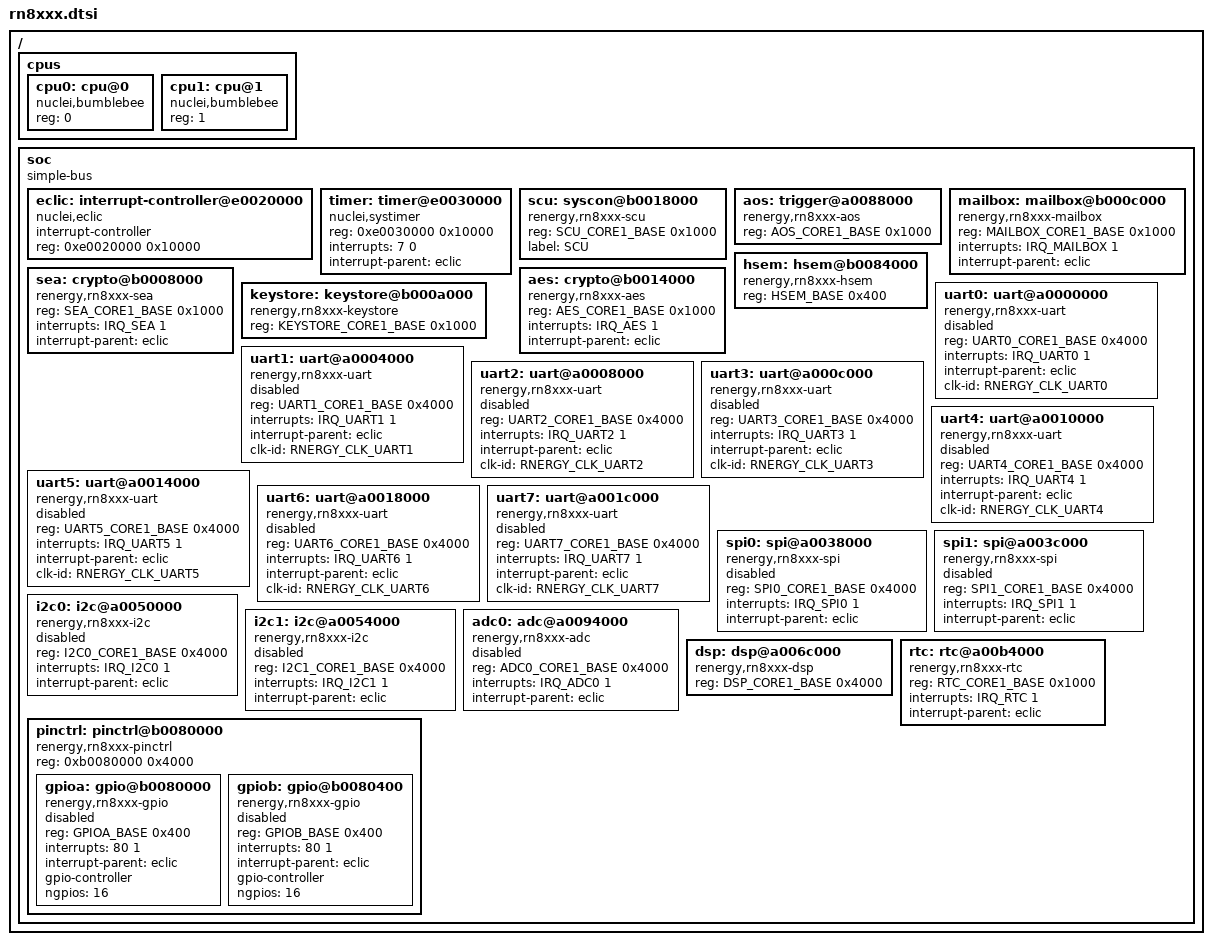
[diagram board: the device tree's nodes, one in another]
/*
 * Copyright (c) 2025 Renergy Technology
 * SPDX-License-Identifier: Apache-2.0
 */

#include <dt-bindings/soc/renergy_rn8xxx.h>
#include <dt-bindings/clock/renergy_rn8xxx_clock.h>

/ {
	#address-cells = <1>;
	#size-cells = <1>;

	cpus {
		#address-cells = <1>;
		#size-cells = <0>;
		cpu0: cpu@0 {
			device_type = "cpu";
			reg = <0>;
			compatible = "nuclei,bumblebee", "riscv";
		};
		cpu1: cpu@1 {
			device_type = "cpu";
			reg = <1>;
			compatible = "nuclei,bumblebee", "riscv";
		};
	};

	soc {
		#address-cells = <1>;
		#size-cells = <1>;
		compatible = "simple-bus";
		ranges;

		/* --- Internal Core Peripherals --- */
		eclic: interrupt-controller@e0020000 {
			compatible = "nuclei,eclic";
			#address-cells = <0>;
			#interrupt-cells = <2>;
			interrupt-controller;
			reg = <0xe0020000 0x10000>;
		};

		timer: timer@e0030000 {
			compatible = "nuclei,systimer";
			reg = <0xe0030000 0x10000>;
			interrupts = <7 0>;
			interrupt-parent = <&eclic>;
		};

		/* --- System & Control --- */
		scu: syscon@b0018000 {
			compatible = "renergy,rn8xxx-scu", "renergy,rn8xxx-clock";
			reg = <SCU_CORE1_BASE 0x1000>;
			#clock-cells = <1>;
			label = "SCU";
		};

		aos: trigger@a0088000 {
			compatible = "renergy,rn8xxx-aos";
			reg = <AOS_CORE1_BASE 0x1000>;
		};

		mailbox: mailbox@b000c000 {
			compatible = "renergy,rn8xxx-mailbox";
			reg = <MAILBOX_CORE1_BASE 0x1000>;
			interrupts = <IRQ_MAILBOX 1>;
			interrupt-parent = <&eclic>;
		};

		hsem: hsem@b0084000 {
			compatible = "renergy,rn8xxx-hsem";
			reg = <HSEM_BASE 0x400>;
		};

		/* --- Security --- */
		sea: crypto@b0008000 {
			compatible = "renergy,rn8xxx-sea";
			reg = <SEA_CORE1_BASE 0x1000>;
			interrupts = <IRQ_SEA 1>;
			interrupt-parent = <&eclic>;
		};

		aes: crypto@b0014000 {
			compatible = "renergy,rn8xxx-aes";
			reg = <AES_CORE1_BASE 0x1000>;
			interrupts = <IRQ_AES 1>;
			interrupt-parent = <&eclic>;
		};

		keystore: keystore@b000a000 {
			compatible = "renergy,rn8xxx-keystore";
			reg = <KEYSTORE_CORE1_BASE 0x1000>;
		};

		/* --- Communications --- */
		uart0: uart@a0000000 { compatible = "renergy,rn8xxx-uart"; reg = <UART0_CORE1_BASE 0x4000>; interrupts = <IRQ_UART0 1>; interrupt-parent = <&eclic>; status = "disabled"; clk-id = <RNERGY_CLK_UART0>; };
		uart1: uart@a0004000 { compatible = "renergy,rn8xxx-uart"; reg = <UART1_CORE1_BASE 0x4000>; interrupts = <IRQ_UART1 1>; interrupt-parent = <&eclic>; status = "disabled"; clk-id = <RNERGY_CLK_UART1>; };
		uart2: uart@a0008000 { compatible = "renergy,rn8xxx-uart"; reg = <UART2_CORE1_BASE 0x4000>; interrupts = <IRQ_UART2 1>; interrupt-parent = <&eclic>; status = "disabled"; clk-id = <RNERGY_CLK_UART2>; };
		uart3: uart@a000c000 { compatible = "renergy,rn8xxx-uart"; reg = <UART3_CORE1_BASE 0x4000>; interrupts = <IRQ_UART3 1>; interrupt-parent = <&eclic>; status = "disabled"; clk-id = <RNERGY_CLK_UART3>; };
		uart4: uart@a0010000 { compatible = "renergy,rn8xxx-uart"; reg = <UART4_CORE1_BASE 0x4000>; interrupts = <IRQ_UART4 1>; interrupt-parent = <&eclic>; status = "disabled"; clk-id = <RNERGY_CLK_UART4>; };
		uart5: uart@a0014000 { compatible = "renergy,rn8xxx-uart"; reg = <UART5_CORE1_BASE 0x4000>; interrupts = <IRQ_UART5 1>; interrupt-parent = <&eclic>; status = "disabled"; clk-id = <RNERGY_CLK_UART5>; };
		uart6: uart@a0018000 { compatible = "renergy,rn8xxx-uart"; reg = <UART6_CORE1_BASE 0x4000>; interrupts = <IRQ_UART6 1>; interrupt-parent = <&eclic>; status = "disabled"; clk-id = <RNERGY_CLK_UART6>; };
		uart7: uart@a001c000 { compatible = "renergy,rn8xxx-uart"; reg = <UART7_CORE1_BASE 0x4000>; interrupts = <IRQ_UART7 1>; interrupt-parent = <&eclic>; status = "disabled"; clk-id = <RNERGY_CLK_UART7>; };

		spi0: spi@a0038000 { compatible = "renergy,rn8xxx-spi"; reg = <SPI0_CORE1_BASE 0x4000>; interrupts = <IRQ_SPI0 1>; interrupt-parent = <&eclic>; status = "disabled"; };
		spi1: spi@a003c000 { compatible = "renergy,rn8xxx-spi"; reg = <SPI1_CORE1_BASE 0x4000>; interrupts = <IRQ_SPI1 1>; interrupt-parent = <&eclic>; status = "disabled"; };

		i2c0: i2c@a0050000 { compatible = "renergy,rn8xxx-i2c"; reg = <I2C0_CORE1_BASE 0x4000>; interrupts = <IRQ_I2C0 1>; interrupt-parent = <&eclic>; status = "disabled"; };
		i2c1: i2c@a0054000 { compatible = "renergy,rn8xxx-i2c"; reg = <I2C1_CORE1_BASE 0x4000>; interrupts = <IRQ_I2C1 1>; interrupt-parent = <&eclic>; status = "disabled"; };

		/* --- Analog & DSP --- */
		adc0: adc@a0094000 {
			compatible = "renergy,rn8xxx-adc";
			reg = <ADC0_CORE1_BASE 0x4000>;
			interrupts = <IRQ_ADC0 1>;
			interrupt-parent = <&eclic>;
			#adc-cells = <1>;
			status = "disabled";
		};

		dsp: dsp@a006c000 {
			compatible = "renergy,rn8xxx-dsp";
			reg = <DSP_CORE1_BASE 0x4000>;
		};

		rtc: rtc@a00b4000 {
			compatible = "renergy,rn8xxx-rtc";
			reg = <RTC_CORE1_BASE 0x1000>;
			interrupts = <IRQ_RTC 1>;
			interrupt-parent = <&eclic>;
		};

		/* --- GPIO Port Blocks (Always use B008xxxx base) --- */
		pinctrl: pinctrl@b0080000 {
			compatible = "renergy,rn8xxx-pinctrl";
			reg = <0xb0080000 0x4000>;

			gpioa: gpio@b0080000 {
				compatible = "renergy,rn8xxx-gpio";
				reg = <GPIOA_BASE 0x400>;
				interrupts = <80 1>;
				interrupt-parent = <&eclic>;
				gpio-controller;
				#gpio-cells = <2>;
				ngpios = <16>;
				status = "disabled";
			};

			gpiob: gpio@b0080400 {
				compatible = "renergy,rn8xxx-gpio";
				reg = <GPIOB_BASE 0x400>;
				interrupts = <80 1>;
				interrupt-parent = <&eclic>;
				gpio-controller;
				#gpio-cells = <2>;
				ngpios = <16>;
				status = "disabled";
			};
		};
	};
};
